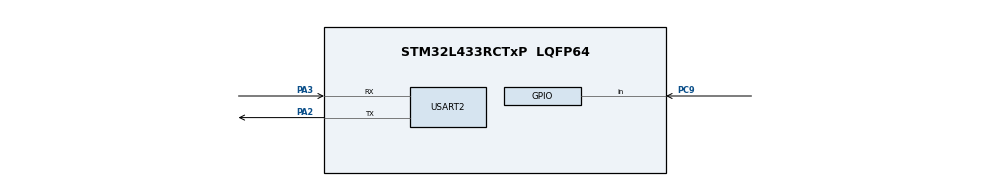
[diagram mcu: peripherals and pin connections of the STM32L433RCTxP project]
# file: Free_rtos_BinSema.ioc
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FREERTOS.BinarySemaphores01=myBinarySem01,Dynamic,NULL,Available
FREERTOS.Tasks01=Task01,24,128,StartTask01,Default,NULL,Dynamic,NULL,NULL;Task02,32,128,StartTask02,Default,NULL,Dynamic,NULL,NULL;Task03,16,128,StartTask03,Default,NULL,Dynamic,NULL,NULL
Mcu.Family=STM32L4
Mcu.Name=STM32L433RCTxP
Mcu.Package=LQFP64
NVIC.PriorityGroup=NVIC_PRIORITYGROUP_4
NVIC.TIM6_DAC_IRQn=true\:15\:0\:false\:false\:true\:false\:false\:true\:true
NVIC.TimeBase=TIM6_DAC_IRQn
NVIC.TimeBaseIP=TIM6
PA13\ (JTMS-SWDIO).Mode=Trace_Asynchronous_SW
PA13\ (JTMS-SWDIO).Signal=SYS_JTMS-SWDIO
PA14\ (JTCK-SWCLK).Mode=Trace_Asynchronous_SW
PA14\ (JTCK-SWCLK).Signal=SYS_JTCK-SWCLK
PA2.Mode=Asynchronous
PA2.Signal=USART2_TX
PA3.Mode=Asynchronous
PA3.Signal=USART2_RX
PB3\ (JTDO-TRACESWO).Mode=Trace_Asynchronous_SW
PB3\ (JTDO-TRACESWO).Signal=SYS_JTDO-SWO
PC9.Signal=GPIO_Input
ProjectManager.HeapSize=0x200
ProjectManager.StackSize=0x400
ProjectManager.TargetToolchain=STM32CubeIDE
RCC.HSE_VALUE=8000000
RCC.HSI48_VALUE=48000000
RCC.HSI_VALUE=16000000
RCC.LSE_VALUE=32768
RCC.MSI_VALUE=4000000
RCC.VCOOutputFreq_Value=32000000
USART2.VirtualMode-Asynchronous=VM_ASYNC
VP_FREERTOS_VS_CMSIS_V2.Mode=CMSIS_V2
VP_SYS_VS_tim6.Mode=TIM6
board=custom

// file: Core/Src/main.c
/* USER CODE BEGIN Header */
/**
  ******************************************************************************
  * @file           : main.c
  * @brief          : Main program body
  ******************************************************************************
  * @attention
  *
  * Copyright (c) 2025 STMicroelectronics.
  * All rights reserved.
  *
  * This software is licensed under terms that can be found in the LICENSE file
  * in the root directory of this software component.
  * If no LICENSE file comes with this software, it is provided AS-IS.
  *
  ******************************************************************************
  */
/* USER CODE END Header */
#include "main.h"
#include "cmsis_os.h"

/* USER CODE BEGIN Includes */
#include <string.h> // STRLEN FUNCTION LIKE
#include <stdio.h> // PRINTF FUNCTION LIKE
/* USER CODE END Includes */

UART_HandleTypeDef huart2;

/* Definitions for Task01 */
osThreadId_t Task01Handle;
const osThreadAttr_t Task01_attributes = {
  .name = "Task01",
  .stack_size = 128 * 4,
  .priority = (osPriority_t) osPriorityNormal,
};
/* Definitions for Task02 */
osThreadId_t Task02Handle;
const osThreadAttr_t Task02_attributes = {
  .name = "Task02",
  .stack_size = 128 * 4,
  .priority = (osPriority_t) osPriorityAboveNormal,
};
/* Definitions for Task03 */
osThreadId_t Task03Handle;
const osThreadAttr_t Task03_attributes = {
  .name = "Task03",
  .stack_size = 128 * 4,
  .priority = (osPriority_t) osPriorityBelowNormal,
};
/* Definitions for myBinarySem01 */
osSemaphoreId_t myBinarySem01Handle;
const osSemaphoreAttr_t myBinarySem01_attributes = {
  .name = "myBinarySem01"
};

void SystemClock_Config(void);
static void MX_GPIO_Init(void);
static void MX_USART2_UART_Init(void);
void StartTask01(void *argument);
void StartTask02(void *argument);
void StartTask03(void *argument);

int main(void)
{

  /* MCU Configuration--------------------------------------------------------*/

  /* Reset of all peripherals, Initializes the Flash interface and the Systick. */
  HAL_Init();

  /* Configure the system clock */
  SystemClock_Config();

  /* Initialize all configured peripherals */
  MX_GPIO_Init();
  MX_USART2_UART_Init();

  /* Init scheduler */
  osKernelInitialize();

  /* Create the semaphores(s) */
  /* creation of myBinarySem01 */
  myBinarySem01Handle = osSemaphoreNew(1, 1, &myBinarySem01_attributes);

  /* Create the thread(s) */
  /* creation of Task01 */
  Task01Handle = osThreadNew(StartTask01, NULL, &Task01_attributes);

  /* creation of Task02 */
  Task02Handle = osThreadNew(StartTask02, NULL, &Task02_attributes);

  /* creation of Task03 */
  Task03Handle = osThreadNew(StartTask03, NULL, &Task03_attributes);

  /* Start scheduler */
  osKernelStart();

  /* We should never get here as control is now taken by the scheduler */

  /* Infinite loop */
  while (1)
  {

  }
}

void SystemClock_Config(void)
{
  RCC_OscInitTypeDef RCC_OscInitStruct = {0};
  RCC_ClkInitTypeDef RCC_ClkInitStruct = {0};

  /** Configure the main internal regulator output voltage
  */
  if (HAL_PWREx_ControlVoltageScaling(PWR_REGULATOR_VOLTAGE_SCALE1) != HAL_OK)
  {
    Error_Handler();
  }

  /** Initializes the RCC Oscillators according to the specified parameters
  * in the RCC_OscInitTypeDef structure.
  */
  RCC_OscInitStruct.OscillatorType = RCC_OSCILLATORTYPE_MSI;
  RCC_OscInitStruct.MSIState = RCC_MSI_ON;
  RCC_OscInitStruct.MSICalibrationValue = 0;
  RCC_OscInitStruct.MSIClockRange = RCC_MSIRANGE_6;
  RCC_OscInitStruct.PLL.PLLState = RCC_PLL_NONE;
  if (HAL_RCC_OscConfig(&RCC_OscInitStruct) != HAL_OK)
  {
    Error_Handler();
  }

  /** Initializes the CPU, AHB and APB buses clocks
  */
  RCC_ClkInitStruct.ClockType = RCC_CLOCKTYPE_HCLK|RCC_CLOCKTYPE_SYSCLK
                              |RCC_CLOCKTYPE_PCLK1|RCC_CLOCKTYPE_PCLK2;
  RCC_ClkInitStruct.SYSCLKSource = RCC_SYSCLKSOURCE_MSI;
  RCC_ClkInitStruct.AHBCLKDivider = RCC_SYSCLK_DIV1;
  RCC_ClkInitStruct.APB1CLKDivider = RCC_HCLK_DIV1;
  RCC_ClkInitStruct.APB2CLKDivider = RCC_HCLK_DIV1;

  if (HAL_RCC_ClockConfig(&RCC_ClkInitStruct, FLASH_LATENCY_0) != HAL_OK)
  {
    Error_Handler();
  }
}

static void MX_USART2_UART_Init(void)
{

  huart2.Instance = USART2;
  huart2.Init.BaudRate = 115200;
  huart2.Init.WordLength = UART_WORDLENGTH_8B;
  huart2.Init.StopBits = UART_STOPBITS_1;
  huart2.Init.Parity = UART_PARITY_NONE;
  huart2.Init.Mode = UART_MODE_TX_RX;
  huart2.Init.HwFlowCtl = UART_HWCONTROL_NONE;
  huart2.Init.OverSampling = UART_OVERSAMPLING_16;
  huart2.Init.OneBitSampling = UART_ONE_BIT_SAMPLE_DISABLE;
  huart2.AdvancedInit.AdvFeatureInit = UART_ADVFEATURE_NO_INIT;
  if (HAL_UART_Init(&huart2) != HAL_OK)
  {
    Error_Handler();
  }

}

static void MX_GPIO_Init(void)
{
  GPIO_InitTypeDef GPIO_InitStruct = {0};

  /* GPIO Ports Clock Enable */
  __HAL_RCC_GPIOA_CLK_ENABLE();
  __HAL_RCC_GPIOC_CLK_ENABLE();
  __HAL_RCC_GPIOB_CLK_ENABLE();

  /*Configure GPIO pin : PC9 */
  GPIO_InitStruct.Pin = GPIO_PIN_9;
  GPIO_InitStruct.Mode = GPIO_MODE_INPUT;
  GPIO_InitStruct.Pull = GPIO_NOPULL;
  HAL_GPIO_Init(GPIOC, &GPIO_InitStruct);

}

void StartTask01(void *argument)
{
  /* USER CODE BEGIN 5 */
  /* Infinite loop */
  for(;;)
  {
	printf("Medium Task Started \n"); // DISPLAY

	osSemaphoreAcquire(myBinarySem01Handle, osWaitForever); // WAIT FOR RELEACE FUNCTION

	printf("Wait for semapore of medium \n"); // DISPLAY

	while( HAL_GPIO_ReadPin(GPIOC, GPIO_PIN_9) == 0); // wait till for low state

	osSemaphoreRelease(myBinarySem01Handle); // STATE RELEASED

	printf("Medium Task Ended \n");// DISPLAY
    osDelay(500); // EVERY 5 MILLISECONDS REPART PROCESS
  }
  /* USER CODE END 5 */
}

void StartTask02(void *argument)
{
  /* USER CODE BEGIN StartTask02 */
  /* Infinite loop */
  for(;;)
  {
	  printf("High task Started \n");// DISPLAY

	  osSemaphoreAcquire(myBinarySem01Handle, osWaitForever); // WAIT FOR RELEASE FUNCTION

	  printf("High Semaphore wait \n");// DISPLAY

	  osSemaphoreRelease(myBinarySem01Handle); // RELEASED THE FUNCTION

	  printf("High Task Ended and release semaphore \n"); // DISPLAY
    osDelay(500);// EVERY 5 MILLISECONDS
  }
  /* USER CODE END StartTask02 */
}

void StartTask03(void *argument)
{
  /* USER CODE BEGIN StartTask03 */
  /* Infinite loop */
  for(;;)
  {
	printf("Low Task Started \n");
	// WITHOUT BINSEMAPHORE AND LOW PRIORITY
	printf("Low Task ended \n");
    osDelay(500);// DISPLAY
  }
  /* USER CODE END StartTask03 */
}

void HAL_TIM_PeriodElapsedCallback(TIM_HandleTypeDef *htim)
{
  if (htim->Instance == TIM6)
  {
    HAL_IncTick();
  }
}

void Error_Handler(void)
{
  __disable_irq();
  while (1)
  {
  }
}
